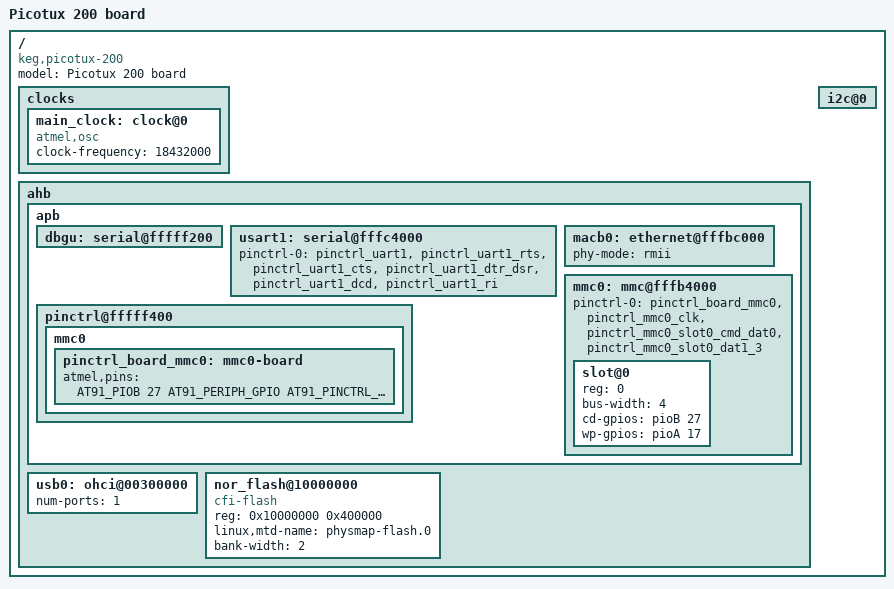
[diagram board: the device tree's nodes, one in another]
/*
 * at91-picotux-200.dts - Device Tree file for Picotux 200 board
 *
 * Copyright (C) 2013 Jean-Christophe PLAGNIOL-VILLARD <plagnioj@jcrosoft.com>
 *
 * Licensed under GPLv2 only
 */
/dts-v1/;
#include "at91rm9200.dtsi"

/ {
	model = "Picotux 200 board";
	compatible = "keg,picotux-200", "atmel,at91rm9200";

	clocks {
		#address-cells = <1>;
		#size-cells = <1>;
		ranges;

		main_clock: clock@0 {
			compatible = "atmel,osc", "fixed-clock";
			clock-frequency = <18432000>;
		};
	};

	ahb {
		apb {
			dbgu: serial@fffff200 {
				status = "okay";
			};

			usart1: serial@fffc4000 {
				pinctrl-0 =
						<&pinctrl_uart1
						 &pinctrl_uart1_rts
						 &pinctrl_uart1_cts
						 &pinctrl_uart1_dtr_dsr
						 &pinctrl_uart1_dcd
						 &pinctrl_uart1_ri>;
				status = "okay";
			};

			macb0: ethernet@fffbc000 {
				phy-mode = "rmii";
				status = "okay";
				/* phy irq on PC4 */
			};

			mmc0: mmc@fffb4000 {
				pinctrl-0 = <
					&pinctrl_board_mmc0
					&pinctrl_mmc0_clk
					&pinctrl_mmc0_slot0_cmd_dat0
					&pinctrl_mmc0_slot0_dat1_3>;
				status = "okay";
				slot@0 {
					reg = <0>;
					bus-width = <4>;
					cd-gpios = <&pioB 27 GPIO_ACTIVE_HIGH>;
					wp-gpios = <&pioA 17 GPIO_ACTIVE_HIGH>;
				};
			};

			pinctrl@fffff400 {
				mmc0 {
					pinctrl_board_mmc0: mmc0-board {
						atmel,pins =
							<AT91_PIOB 27 AT91_PERIPH_GPIO AT91_PINCTRL_PULL_UP_DEGLITCH
							 AT91_PIOA 17 AT91_PERIPH_GPIO AT91_PINCTRL_PULL_UP>;
					};
				};
			};
		};

		usb0: ohci@00300000 {
			num-ports = <1>;
			status = "okay";
		};

		nor_flash@10000000 {
			compatible = "cfi-flash";
			reg = <0x10000000 0x400000>;
			linux,mtd-name = "physmap-flash.0";
			bank-width = <2>;
			#address-cells = <1>;
			#size-cells = <1>;
		};
	};

	i2c@0 {
		status = "okay";
	};
};
